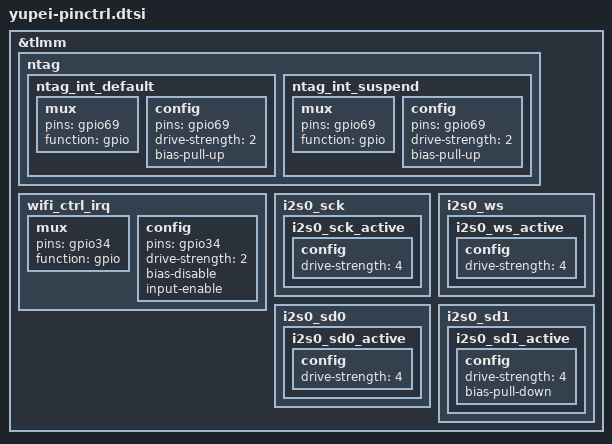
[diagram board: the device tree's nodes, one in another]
/*for yupei pinctrl */
&tlmm {
	ntag {
		ntag_int_default: ntag_int_default {
			mux {
				pins = "gpio69";
				function = "gpio";
			};

			config {
				pins = "gpio69";
				drive-strength = <2>; /* 2 MA */
				bias-pull-up;
			};
		};

		ntag_int_suspend: ntag_int_suspend {
			mux {
				pins = "gpio69";
				function = "gpio";
			};

			config {
				pins = "gpio69";
				drive-strength = <2>; /* 2 MA */
				bias-pull-up;
			};
		};
	}; //ntag

	wifi_ctrl_irq: wifi_ctrl_irq {
		mux {
                pins = "gpio34";
                function = "gpio";
         };

	config {
                pins = "gpio34";
                drive-strength = <2>;   /* 2 mA */
                bias-disable;
                input-enable;
        };
    }; //wifi
	i2s0_sck {
		i2s0_sck_active {
			config {
				drive-strength = <4>;   /* 4 mA */
			};
		};
	};

	i2s0_ws {
		i2s0_ws_active {
			config {
				drive-strength = <4>;   /* 4 mA */
			};
		};
	};

	i2s0_sd0 {
		i2s0_sd0_active{
			config {
				drive-strength = <4>;   /* 4 mA */
			};
		};
	};

	i2s0_sd1 {
		i2s0_sd1_active {
			config {
				drive-strength = <4>;   /* 4 mA */
				bias-pull-down;         /* power down */
			};
		};
	};

}; //tlmm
